AUTOSAR XML (schema 4-2-2)
package /STELLANTIS/EPT/ASWCs
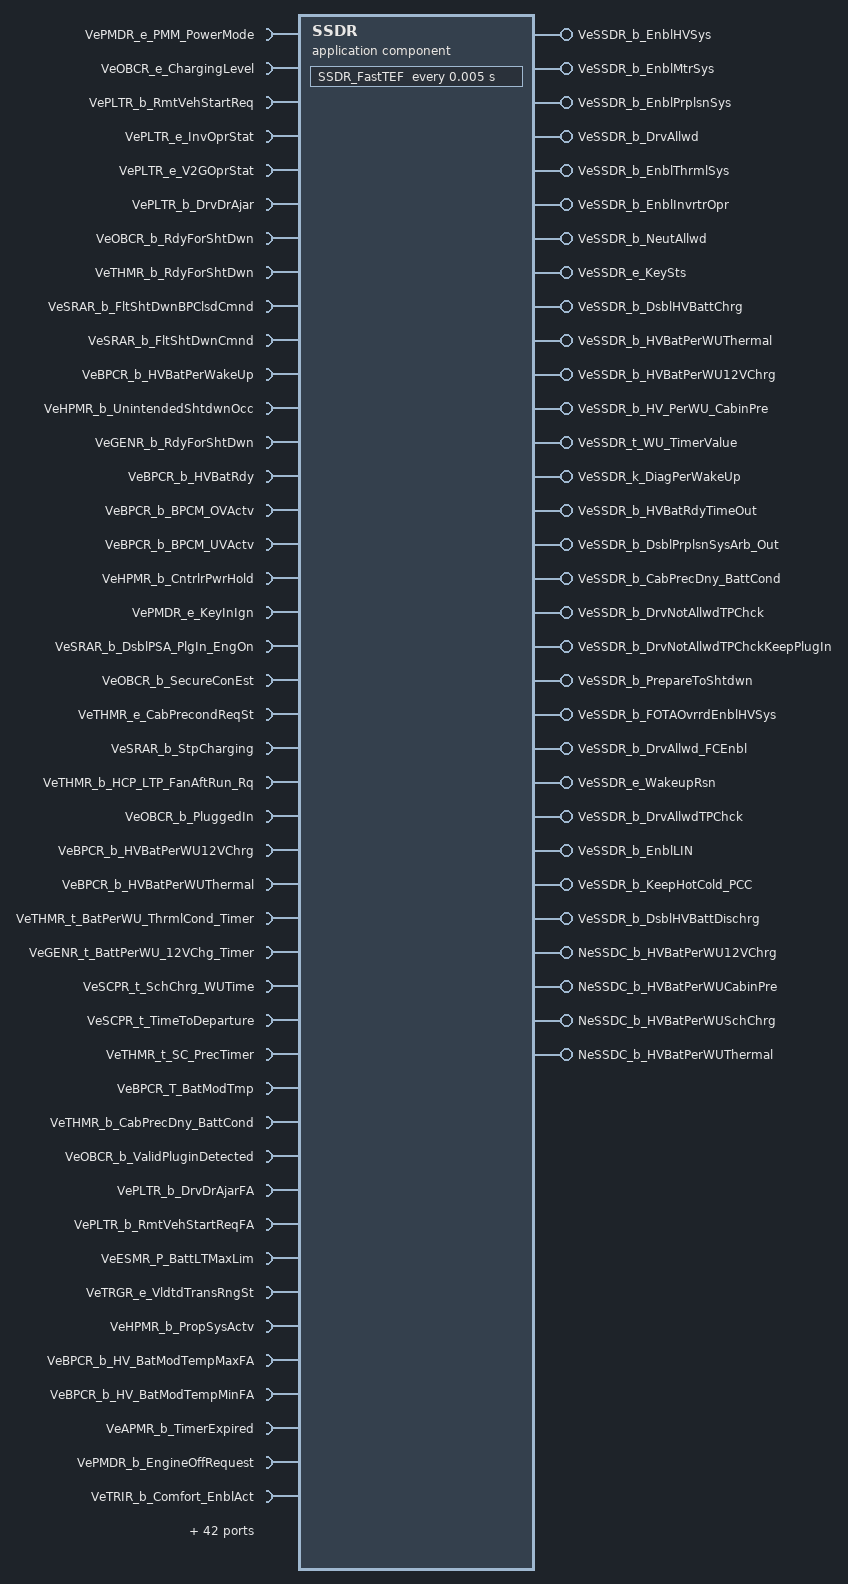
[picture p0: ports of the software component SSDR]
  application sw component type SSDR
    82 x require port:
      VePMDR_e_PMM_PowerMode: nonqueued-receiver-com-spec{data-element=Value, init-value=CePMDR_e_PowerMode_Off}, required-interface=VePMDR_e_PMM_PowerMode
      VeOBCR_e_ChargingLevel: nonqueued-receiver-com-spec{data-element=Value, init-value=CeOBCR_e_ChargingLvlDefault}, required-interface=VeOBCR_e_ChargingLevel
      VePLTR_b_RmtVehStartReq: nonqueued-receiver-com-spec{data-element=Value, init-value=0}, required-interface=VePLTR_b_RmtVehStartReq
      VePLTR_e_InvOprStat: nonqueued-receiver-com-spec{data-element=Value, init-value=CePLTR_e_NoPlgIn_Tools}, required-interface=VePLTR_e_InvOprStat
      VePLTR_e_V2GOprStat: nonqueued-receiver-com-spec{data-element=Value, init-value=CePLTR_e_NoPlgIn}, required-interface=VePLTR_e_V2GOprStat
      VePLTR_b_DrvDrAjar: nonqueued-receiver-com-spec{data-element=Value, init-value=0}, required-interface=VePLTR_b_DrvDrAjar
      VeOBCR_b_RdyForShtDwn: nonqueued-receiver-com-spec{data-element=Value, init-value=0}, required-interface=VeOBCR_b_RdyForShtDwn
      VeTHMR_b_RdyForShtDwn: nonqueued-receiver-com-spec{data-element=Value, init-value=0}, required-interface=VeTHMR_b_RdyForShtDwn
      VeSRAR_b_FltShtDwnBPClsdCmnd: nonqueued-receiver-com-spec{data-element=Value, init-value=0}, required-interface=VeSRAR_b_FltShtDwnBPClsdCmnd
      VeSRAR_b_FltShtDwnCmnd: nonqueued-receiver-com-spec{data-element=Value, init-value=0}, required-interface=VeSRAR_b_FltShtDwnCmnd
      VeBPCR_b_HVBatPerWakeUp: nonqueued-receiver-com-spec{data-element=Value, init-value=0}, required-interface=VeBPCR_b_HVBatPerWakeUp
      VeHPMR_b_UnintendedShtdwnOcc: nonqueued-receiver-com-spec{data-element=Value, init-value=0}, required-interface=VeHPMR_b_UnintendedShtdwnOcc
      VeGENR_b_RdyForShtDwn: nonqueued-receiver-com-spec{data-element=Value, init-value=0}, required-interface=VeGENR_b_RdyForShtDwn
      VeBPCR_b_HVBatRdy: nonqueued-receiver-com-spec{data-element=Value, init-value=0}, required-interface=VeBPCR_b_HVBatRdy
      VeBPCR_b_BPCM_OVActv: nonqueued-receiver-com-spec{data-element=Value, init-value=0}, required-interface=VeBPCR_b_BPCM_OVActv
      VeBPCR_b_BPCM_UVActv: nonqueued-receiver-com-spec{data-element=Value, init-value=0}, required-interface=VeBPCR_b_BPCM_UVActv
      VeHPMR_b_CntrlrPwrHold: nonqueued-receiver-com-spec{data-element=Value, init-value=0}, required-interface=VeHPMR_b_CntrlrPwrHold
      VePMDR_e_KeyInIgn: nonqueued-receiver-com-spec{data-element=Value, init-value=CePMDR_e_KeyInIgn_DEFAULT}, required-interface=VePMDR_e_KeyInIgn
      VeSRAR_b_DsblPSA_PlgIn_EngOn: nonqueued-receiver-com-spec{data-element=Value, init-value=0}, required-interface=VeSRAR_b_DsblPSA_PlgIn_EngOn
      VeOBCR_b_SecureConEst: nonqueued-receiver-com-spec{data-element=Value, init-value=0}, required-interface=VeOBCR_b_SecureConEst
      VeTHMR_e_CabPrecondReqSt: nonqueued-receiver-com-spec{data-element=Value, init-value=CeTPCR_e_CabinPrec_Dflt}, required-interface=VeTHMR_e_CabPrecondReqSt
      VeSRAR_b_StpCharging: nonqueued-receiver-com-spec{data-element=Value, init-value=0}, required-interface=VeSRAR_b_StpCharging
      VeTHMR_b_HCP_LTP_FanAftRun_Rq: nonqueued-receiver-com-spec{data-element=Value, init-value=0}, required-interface=VeTHMR_b_HCP_LTP_FanAftRun_Rq
      VeOBCR_b_PluggedIn: nonqueued-receiver-com-spec{data-element=Value, init-value=0}, required-interface=VeOBCR_b_PluggedIn
      VeBPCR_b_HVBatPerWU12VChrg: nonqueued-receiver-com-spec{data-element=Value, init-value=0}, required-interface=VeBPCR_b_HVBatPerWU12VChrg
      VeBPCR_b_HVBatPerWUThermal: nonqueued-receiver-com-spec{data-element=Value, init-value=0}, required-interface=VeBPCR_b_HVBatPerWUThermal
      VeTHMR_t_BatPerWU_ThrmlCond_Timer: nonqueued-receiver-com-spec{data-element=Value, init-value=0}, required-interface=VeTHMR_t_BatPerWU_ThrmlCond_Timer
      VeGENR_t_BattPerWU_12VChg_Timer: nonqueued-receiver-com-spec{data-element=Value, init-value=0}, required-interface=VeGENR_t_BattPerWU_12VChg_Timer
      VeSCPR_t_SchChrg_WUTime: nonqueued-receiver-com-spec{data-element=Value, init-value=0}, required-interface=VeSCPR_t_SchChrg_WUTime
      VeSCPR_t_TimeToDeparture: nonqueued-receiver-com-spec{data-element=Value, init-value=0}, required-interface=VeSCPR_t_TimeToDeparture
      VeTHMR_t_SC_PrecTimer: nonqueued-receiver-com-spec{data-element=Value, init-value=0}, required-interface=VeTHMR_t_SC_PrecTimer
      VeBPCR_T_BatModTmp: nonqueued-receiver-com-spec{data-element=Value, init-value=0}, required-interface=VeBPCR_T_BatModTmp
      VeTHMR_b_CabPrecDny_BattCond: nonqueued-receiver-com-spec{data-element=Value, init-value=0}, required-interface=VeTHMR_b_CabPrecDny_BattCond
      VeOBCR_b_ValidPluginDetected: nonqueued-receiver-com-spec{data-element=Value, init-value=0}, required-interface=VeOBCR_b_ValidPluginDetected
      VePLTR_b_DrvDrAjarFA: nonqueued-receiver-com-spec{data-element=Value, init-value=0}, required-interface=VePLTR_b_DrvDrAjarFA
      VePLTR_b_RmtVehStartReqFA: nonqueued-receiver-com-spec{data-element=Value, init-value=0}, required-interface=VePLTR_b_RmtVehStartReqFA
      VeESMR_P_BattLTMaxLim: nonqueued-receiver-com-spec{data-element=Value, init-value=0}, required-interface=VeESMR_P_BattLTMaxLim
      VeTRGR_e_VldtdTransRngSt: nonqueued-receiver-com-spec{data-element=Value, init-value=CeTRGR_e_NoSelectionAvailable}, required-interface=VeTRGR_e_VldtdTransRngSt
      VeHPMR_b_PropSysActv: nonqueued-receiver-com-spec{data-element=Value, init-value=0}, required-interface=VeHPMR_b_PropSysActv
      VeBPCR_b_HV_BatModTempMaxFA: nonqueued-receiver-com-spec{data-element=Value, init-value=0}, required-interface=VeBPCR_b_HV_BatModTempMaxFA
      VeBPCR_b_HV_BatModTempMinFA: nonqueued-receiver-com-spec{data-element=Value, init-value=0}, required-interface=VeBPCR_b_HV_BatModTempMinFA
      VeAPMR_b_TimerExpired: nonqueued-receiver-com-spec{data-element=Value, init-value=0}, required-interface=VeAPMR_b_TimerExpired
      VePMDR_b_EngineOffRequest: nonqueued-receiver-com-spec{data-element=Value, init-value=0}, required-interface=VePMDR_b_EngineOffRequest
      VeTRIR_b_Comfort_EnblAct: nonqueued-receiver-com-spec{data-element=Value, init-value=0}, required-interface=VeTRIR_b_Comfort_EnblAct
      VeTPCR_e_KeepHotColdSts: nonqueued-receiver-com-spec{data-element=Value, init-value=CeTPCR_e_NotActive}, required-interface=VeTPCR_e_KeepHotColdSts
      VeBRKR_e_BrkPedalDscrtInpt: nonqueued-receiver-com-spec{data-element=Value, init-value=CeBRKR_e_BrkNotApplied}, required-interface=VeBRKR_e_BrkPedalDscrtInpt
      VeTRGR_e_ESMTransRngSt: nonqueued-receiver-com-spec{data-element=Value, init-value=CeTRGR_e_NoSelectionAvailable}, required-interface=VeTRGR_e_ESMTransRngSt
      VePLTR_e_LSMDExtReleaseLockReq: nonqueued-receiver-com-spec{data-element=Value, init-value=CePLTR_e_NotActive}, required-interface=VePLTR_e_LSMDExtReleaseLockReq
      VePLTR_b_HotEnablerReq: nonqueued-receiver-com-spec{data-element=Value, init-value=0}, required-interface=VePLTR_b_HotEnablerReq
      VeSCPR_e_InitStatus: nonqueued-receiver-com-spec{data-element=Value, init-value=CeSCPR_e_InitDefault}, required-interface=VeSCPR_e_InitStatus
      VePMTR_b_ThrmlShtdwnReqHonrd: nonqueued-receiver-com-spec{data-element=Value, init-value=0}, required-interface=VePMTR_b_ThrmlShtdwnReqHonrd
      VeHPMR_b_PrepareToShtdwn: nonqueued-receiver-com-spec{data-element=Value, init-value=0}, required-interface=VeHPMR_b_PrepareToShtdwn
      VeCITR_e_FOTA_Install_Type: nonqueued-receiver-com-spec{data-element=Value, init-value=CeCITR_e_NoFOTA}, required-interface=VeCITR_e_FOTA_Install_Type
      VeSCPR_b_FOTASchCnflct: nonqueued-receiver-com-spec{data-element=Value, init-value=0}, required-interface=VeSCPR_b_FOTASchCnflct
      VeFCPR_e_FCPS_HTCoolReq: nonqueued-receiver-com-spec{data-element=Value, init-value=CeFCPR_e_No_Request}, required-interface=VeFCPR_e_FCPS_HTCoolReq
      VeFCPR_e_ActualMode: nonqueued-receiver-com-spec{data-element=Value, init-value=CeFCPR_e_ActualMode_NotAvailable}, required-interface=VeFCPR_e_ActualMode
      VeBPCR_e_HV_BatCntctrStat: nonqueued-receiver-com-spec{data-element=Value, init-value=CeHVTR_e_Open}, required-interface=VeBPCR_e_HV_BatCntctrStat
      VeCITR_b_ChargeNow: nonqueued-receiver-com-spec{data-element=Value, init-value=0}, required-interface=VeCITR_b_ChargeNow
      VeCITR_b_TBM_ChargeNow: nonqueued-receiver-com-spec{data-element=Value, init-value=0}, required-interface=VeCITR_b_TBM_ChargeNow
      VeCITR_b_TBM_Sch1_Submit: nonqueued-receiver-com-spec{data-element=Value, init-value=0}, required-interface=VeCITR_b_TBM_Sch1_Submit
      VeCITR_b_HU_Sch1_Submit: nonqueued-receiver-com-spec{data-element=Value, init-value=0}, required-interface=VeCITR_b_HU_Sch1_Submit
      VeCITR_b_TBM_Sch2_Submit: nonqueued-receiver-com-spec{data-element=Value, init-value=0}, required-interface=VeCITR_b_TBM_Sch2_Submit
      VeCITR_b_HU_Sch2_Submit: nonqueued-receiver-com-spec{data-element=Value, init-value=0}, required-interface=VeCITR_b_HU_Sch2_Submit
      VeCITR_b_HU_Sch3_Submit: nonqueued-receiver-com-spec{data-element=Value, init-value=0}, required-interface=VeCITR_b_HU_Sch3_Submit
      VeCITR_b_TBM_Sch3_Submit: nonqueued-receiver-com-spec{data-element=Value, init-value=0}, required-interface=VeCITR_b_TBM_Sch3_Submit
      VeCITR_b_HU_Sch4_Submit: nonqueued-receiver-com-spec{data-element=Value, init-value=0}, required-interface=VeCITR_b_HU_Sch4_Submit
      VeCITR_b_TBM_Sch4_Submit: nonqueued-receiver-com-spec{data-element=Value, init-value=0}, required-interface=VeCITR_b_TBM_Sch4_Submit
      VeTRGR_b_Secured_To_Shtdwn: nonqueued-receiver-com-spec{data-element=Value, init-value=0}, required-interface=VeTRGR_b_Secured_To_Shtdwn
      VeVTLR_b_Rdy4ShtDwn: nonqueued-receiver-com-spec{data-element=Value, init-value=0}, required-interface=VeVTLR_b_Rdy4ShtDwn
      VeOBCR_b_SecureConnV2L: nonqueued-receiver-com-spec{data-element=Value, init-value=0}, required-interface=VeOBCR_b_SecureConnV2L
      VeESSR_e_EngStartStopSt: nonqueued-receiver-com-spec{data-element=Value, init-value=CeESSR_e_EngOff}, required-interface=VeESSR_e_EngStartStopSt
      VeBPCR_Pct_HV_BatPackSOC_Arb: nonqueued-receiver-com-spec{data-element=Value, init-value=0}, required-interface=VeBPCR_Pct_HV_BatPackSOC_Arb
      VeVTLR_b_OnboardPP1_Dtctd: nonqueued-receiver-com-spec{data-element=Value, init-value=0}, required-interface=VeVTLR_b_OnboardPP1_Dtctd
      VeVTLR_b_OnboardPP2_Dtctd: nonqueued-receiver-com-spec{data-element=Value, init-value=0}, required-interface=VeVTLR_b_OnboardPP2_Dtctd
      VeVTLR_b_Rdy4ShtDwn_OnboardPP1: nonqueued-receiver-com-spec{data-element=Value, init-value=0}, required-interface=VeVTLR_b_Rdy4ShtDwn_OnboardPP1
      VeVTLR_b_Rdy4ShtDwn_OnboardPP2: nonqueued-receiver-com-spec{data-element=Value, init-value=0}, required-interface=VeVTLR_b_Rdy4ShtDwn_OnboardPP2
      VeHPMR_b_HVFltStpChrg: nonqueued-receiver-com-spec{data-element=Value, init-value=0}, required-interface=VeHPMR_b_HVFltStpChrg
      VePLTR_b_InFieldMode: nonqueued-receiver-com-spec{data-element=Value, init-value=0}, required-interface=VePLTR_b_InFieldMode
      VeTRIR_b_Comfort_EnblAct_FA: nonqueued-receiver-com-spec{data-element=Value, init-value=0}, required-interface=VeTRIR_b_Comfort_EnblAct_FA
      VeVDVR_b_Rdy4ShtDwn: nonqueued-receiver-com-spec{data-element=Value, init-value=0}, required-interface=VeVDVR_b_Rdy4ShtDwn
      VeBPCR_b_HV_AuxLoadOffReq: nonqueued-receiver-com-spec{data-element=Value, init-value=0}, required-interface=VeBPCR_b_HV_AuxLoadOffReq
      VeHPMR_e_HybSysSt: nonqueued-receiver-com-spec{data-element=Value, init-value=CeHPMR_e_POWERUP}, required-interface=VeHPMR_e_HybSysSt
    27 x provide port:
      VeSSDR_b_EnblHVSys: nonqueued-sender-com-spec{data-element=Value, init-value=0}, provided-interface=VeSSDR_b_EnblHVSys
      VeSSDR_b_EnblMtrSys: nonqueued-sender-com-spec{data-element=Value, init-value=0}, provided-interface=VeSSDR_b_EnblMtrSys
      VeSSDR_b_EnblPrplsnSys: nonqueued-sender-com-spec{data-element=Value, init-value=0}, provided-interface=VeSSDR_b_EnblPrplsnSys
      VeSSDR_b_DrvAllwd: nonqueued-sender-com-spec{data-element=Value, init-value=0}, provided-interface=VeSSDR_b_DrvAllwd
      VeSSDR_b_EnblThrmlSys: nonqueued-sender-com-spec{data-element=Value, init-value=0}, provided-interface=VeSSDR_b_EnblThrmlSys
      VeSSDR_b_EnblInvrtrOpr: nonqueued-sender-com-spec{data-element=Value, init-value=0}, provided-interface=VeSSDR_b_EnblInvrtrOpr
      VeSSDR_b_NeutAllwd: nonqueued-sender-com-spec{data-element=Value, init-value=0}, provided-interface=VeSSDR_b_NeutAllwd
      VeSSDR_e_KeySts: nonqueued-sender-com-spec{data-element=Value, init-value=CeSSDR_e_KeyOff}, provided-interface=VeSSDR_e_KeySts
      VeSSDR_b_DsblHVBattChrg: nonqueued-sender-com-spec{data-element=Value, init-value=0}, provided-interface=VeSSDR_b_DsblHVBattChrg
      VeSSDR_b_HVBatPerWUThermal: nonqueued-sender-com-spec{data-element=Value, init-value=0}, provided-interface=VeSSDR_b_HVBatPerWUThermal
      VeSSDR_b_HVBatPerWU12VChrg: nonqueued-sender-com-spec{data-element=Value, init-value=0}, provided-interface=VeSSDR_b_HVBatPerWU12VChrg
      VeSSDR_b_HV_PerWU_CabinPre: nonqueued-sender-com-spec{data-element=Value, init-value=0}, provided-interface=VeSSDR_b_HV_PerWU_CabinPre
      VeSSDR_t_WU_TimerValue: nonqueued-sender-com-spec{data-element=Value, init-value=0}, provided-interface=VeSSDR_t_WU_TimerValue
      VeSSDR_k_DiagPerWakeUp: nonqueued-sender-com-spec{data-element=Value, init-value=0}, provided-interface=VeSSDR_k_DiagPerWakeUp
      VeSSDR_b_HVBatRdyTimeOut: nonqueued-sender-com-spec{data-element=Value, init-value=0}, provided-interface=VeSSDR_b_HVBatRdyTimeOut
      VeSSDR_b_DsblPrplsnSysArb_Out: nonqueued-sender-com-spec{data-element=Value, init-value=0}, provided-interface=VeSSDR_b_DsblPrplsnSysArb_Out
      VeSSDR_b_CabPrecDny_BattCond: nonqueued-sender-com-spec{data-element=Value, init-value=0}, provided-interface=VeSSDR_b_CabPrecDny_BattCond
      VeSSDR_b_DrvNotAllwdTPChck: nonqueued-sender-com-spec{data-element=Value, init-value=0}, provided-interface=VeSSDR_b_DrvNotAllwdTPChck
      VeSSDR_b_DrvNotAllwdTPChckKeepPlugIn: nonqueued-sender-com-spec{data-element=Value, init-value=0}, provided-interface=VeSSDR_b_DrvNotAllwdTPChckKeepPlugIn
      VeSSDR_b_PrepareToShtdwn: nonqueued-sender-com-spec{data-element=Value, init-value=0}, provided-interface=VeSSDR_b_PrepareToShtdwn
      VeSSDR_b_FOTAOvrrdEnblHVSys: nonqueued-sender-com-spec{data-element=Value, init-value=0}, provided-interface=VeSSDR_b_FOTAOvrrdEnblHVSys
      VeSSDR_b_DrvAllwd_FCEnbl: nonqueued-sender-com-spec{data-element=Value, init-value=0}, provided-interface=VeSSDR_b_DrvAllwd_FCEnbl
      VeSSDR_e_WakeupRsn: nonqueued-sender-com-spec{data-element=Value, init-value=0}, provided-interface=VeSSDR_e_WakeupRsn
      VeSSDR_b_DrvAllwdTPChck: nonqueued-sender-com-spec{data-element=Value, init-value=0}, provided-interface=VeSSDR_b_DrvAllwdTPChck
      VeSSDR_b_EnblLIN: nonqueued-sender-com-spec{data-element=Value, init-value=0}, provided-interface=VeSSDR_b_EnblLIN
      VeSSDR_b_KeepHotCold_PCC: nonqueued-sender-com-spec{data-element=Value, init-value=0}, provided-interface=VeSSDR_b_KeepHotCold_PCC
      VeSSDR_b_DsblHVBattDischrg: nonqueued-sender-com-spec{data-element=Value, init-value=0}, provided-interface=VeSSDR_b_DsblHVBattDischrg
    4 x require port:
      NeSSDC_b_HVBatPerWU12VChrg_Rx: nv-require-com-spec{init-value=0, variable=NeSSDC_b_HVBatPerWU12VChrg}, required-interface=NeSSDC_b_HVBatPerWU12VChrg
      NeSSDC_b_HVBatPerWUCabinPre_Rx: nv-require-com-spec{init-value=0, variable=NeSSDC_b_HVBatPerWUCabinPre}, required-interface=NeSSDC_b_HVBatPerWUCabinPre
      NeSSDC_b_HVBatPerWUSchChrg_Rx: nv-require-com-spec{init-value=0, variable=NeSSDC_b_HVBatPerWUSchChrg}, required-interface=NeSSDC_b_HVBatPerWUSchChrg
      NeSSDC_b_HVBatPerWUThermal_Rx: nv-require-com-spec{init-value=0, variable=NeSSDC_b_HVBatPerWUThermal}, required-interface=NeSSDC_b_HVBatPerWUThermal
    4 x provide port:
      NeSSDC_b_HVBatPerWU12VChrg: nv-provide-com-spec{ram-block-init-value=0, variable=NeSSDC_b_HVBatPerWU12VChrg}, provided-interface=NeSSDC_b_HVBatPerWU12VChrg
      NeSSDC_b_HVBatPerWUCabinPre: nv-provide-com-spec{ram-block-init-value=0, variable=NeSSDC_b_HVBatPerWUCabinPre}, provided-interface=NeSSDC_b_HVBatPerWUCabinPre
      NeSSDC_b_HVBatPerWUSchChrg: nv-provide-com-spec{ram-block-init-value=0, variable=NeSSDC_b_HVBatPerWUSchChrg}, provided-interface=NeSSDC_b_HVBatPerWUSchChrg
      NeSSDC_b_HVBatPerWUThermal: nv-provide-com-spec{ram-block-init-value=0, variable=NeSSDC_b_HVBatPerWUThermal}, provided-interface=NeSSDC_b_HVBatPerWUThermal
    behavior IB_SSDR: data-type-mapping=msADTtoIDTMapping, handle-termination-and-restart=NO-SUPPORT, included-data-type-set=data-type=[TeSSDR_e_HVBattChrgStat, TeSSDR_e_InvOprStat, TeSSDR_e_V2GOprStat]
      timing event Event_FastTEF: start-on-event=SSDR_FastTEF, period=0.005
      init event Event_SSDR_ac_Init: start-on-event=SSDR_ac_Init
      init event Event_PwrOn: start-on-event=SSDR_PwrOn
      init event Event_PwrOff: start-on-event=SSDR_PwrOff
      4 x runnable:
        SSDR_ac_Init
          data-send-points:
            access OUT_VeSSDR_e_KeySts_Value: accessed-variable=VeSSDR_e_KeySts.Value
        SSDR_PwrOn
          data-receive-point-by-arguments:
            4 x access:
              IN_NeSSDC_b_HVBatPerWU12VChrg_Rx_NeSSDC_b_HVBatPerWU12VChrg: accessed-variable=NeSSDC_b_HVBatPerWU12VChrg_Rx.NeSSDC_b_HVBatPerWU12VChrg
              IN_NeSSDC_b_HVBatPerWUCabinPre_Rx_NeSSDC_b_HVBatPerWUCabinPre: accessed-variable=NeSSDC_b_HVBatPerWUCabinPre_Rx.NeSSDC_b_HVBatPerWUCabinPre
              IN_NeSSDC_b_HVBatPerWUSchChrg_Rx_NeSSDC_b_HVBatPerWUSchChrg: accessed-variable=NeSSDC_b_HVBatPerWUSchChrg_Rx.NeSSDC_b_HVBatPerWUSchChrg
              IN_NeSSDC_b_HVBatPerWUThermal_Rx_NeSSDC_b_HVBatPerWUThermal: accessed-variable=NeSSDC_b_HVBatPerWUThermal_Rx.NeSSDC_b_HVBatPerWUThermal
          data-send-points:
            27 x access:
              OUT_VeSSDR_b_EnblHVSys_Value: accessed-variable=VeSSDR_b_EnblHVSys.Value
              OUT_VeSSDR_b_EnblMtrSys_Value: accessed-variable=VeSSDR_b_EnblMtrSys.Value
              OUT_VeSSDR_b_NeutAllwd_Value: accessed-variable=VeSSDR_b_NeutAllwd.Value
              OUT_VeSSDR_e_KeySts_Value: accessed-variable=VeSSDR_e_KeySts.Value
              OUT_VeSSDR_e_WakeupRsn_Value: accessed-variable=VeSSDR_e_WakeupRsn.Value
              OUT_VeSSDR_b_DsblHVBattChrg_Value: accessed-variable=VeSSDR_b_DsblHVBattChrg.Value
              OUT_VeSSDR_b_HVBatPerWUThermal_Value: accessed-variable=VeSSDR_b_HVBatPerWUThermal.Value
              OUT_VeSSDR_b_HVBatPerWU12VChrg_Value: accessed-variable=VeSSDR_b_HVBatPerWU12VChrg.Value
              OUT_VeSSDR_b_DrvAllwdTPChck_Value: accessed-variable=VeSSDR_b_DrvAllwdTPChck.Value
              OUT_VeSSDR_b_HV_PerWU_CabinPre_Value: accessed-variable=VeSSDR_b_HV_PerWU_CabinPre.Value
              OUT_VeSSDR_t_WU_TimerValue_Value: accessed-variable=VeSSDR_t_WU_TimerValue.Value
              OUT_VeSSDR_b_HVBatRdyTimeOut_Value: accessed-variable=VeSSDR_b_HVBatRdyTimeOut.Value
              OUT_VeSSDR_b_EnblPrplsnSys_Value: accessed-variable=VeSSDR_b_EnblPrplsnSys.Value
              OUT_VeSSDR_b_DsblPrplsnSysArb_Out_Value: accessed-variable=VeSSDR_b_DsblPrplsnSysArb_Out.Value
              OUT_VeSSDR_b_CabPrecDny_BattCond_Value: accessed-variable=VeSSDR_b_CabPrecDny_BattCond.Value
              OUT_VeSSDR_k_DiagPerWakeUp_Value: accessed-variable=VeSSDR_k_DiagPerWakeUp.Value
              OUT_VeSSDR_b_DrvNotAllwdTPChck_Value: accessed-variable=VeSSDR_b_DrvNotAllwdTPChck.Value
              OUT_VeSSDR_b_EnblLIN_Value: accessed-variable=VeSSDR_b_EnblLIN.Value
              OUT_VeSSDR_b_KeepHotCold_PCC_Value: accessed-variable=VeSSDR_b_KeepHotCold_PCC.Value
              OUT_VeSSDR_b_DrvAllwd_Value: accessed-variable=VeSSDR_b_DrvAllwd.Value
              OUT_VeSSDR_b_DrvNotAllwdTPChckKeepPlugIn_Value: accessed-variable=VeSSDR_b_DrvNotAllwdTPChckKeepPlugIn.Value
              OUT_VeSSDR_b_EnblThrmlSys_Value: accessed-variable=VeSSDR_b_EnblThrmlSys.Value
              OUT_VeSSDR_b_EnblInvrtrOpr_Value: accessed-variable=VeSSDR_b_EnblInvrtrOpr.Value
              OUT_VeSSDR_b_PrepareToShtdwn_Value: accessed-variable=VeSSDR_b_PrepareToShtdwn.Value
              OUT_VeSSDR_b_FOTAOvrrdEnblHVSys_Value: accessed-variable=VeSSDR_b_FOTAOvrrdEnblHVSys.Value
              OUT_VeSSDR_b_DrvAllwd_FCEnbl_Value: accessed-variable=VeSSDR_b_DrvAllwd_FCEnbl.Value
              OUT_VeSSDR_b_DsblHVBattDischrg_Value: accessed-variable=VeSSDR_b_DsblHVBattDischrg.Value
        SSDR_FastTEF
          data-receive-point-by-arguments:
            82 x access:
              IN_VeAPMR_b_TimerExpired_Value: accessed-variable=VeAPMR_b_TimerExpired.Value
              IN_VeBPCR_Pct_HV_BatPackSOC_Arb_Value: accessed-variable=VeBPCR_Pct_HV_BatPackSOC_Arb.Value
              IN_VeBPCR_T_BatModTmp_Value: accessed-variable=VeBPCR_T_BatModTmp.Value
              IN_VeBPCR_b_BPCM_OVActv_Value: accessed-variable=VeBPCR_b_BPCM_OVActv.Value
              IN_VeBPCR_b_BPCM_UVActv_Value: accessed-variable=VeBPCR_b_BPCM_UVActv.Value
              IN_VeBPCR_b_HVBatPerWU12VChrg_Value: accessed-variable=VeBPCR_b_HVBatPerWU12VChrg.Value
              IN_VeBPCR_b_HVBatPerWUThermal_Value: accessed-variable=VeBPCR_b_HVBatPerWUThermal.Value
              IN_VeBPCR_b_HVBatPerWakeUp_Value: accessed-variable=VeBPCR_b_HVBatPerWakeUp.Value
              IN_VeBPCR_b_HVBatRdy_Value: accessed-variable=VeBPCR_b_HVBatRdy.Value
              IN_VeBPCR_b_HV_AuxLoadOffReq_Value: accessed-variable=VeBPCR_b_HV_AuxLoadOffReq.Value
              IN_VeBPCR_b_HV_BatModTempMaxFA_Value: accessed-variable=VeBPCR_b_HV_BatModTempMaxFA.Value
              IN_VeBPCR_b_HV_BatModTempMinFA_Value: accessed-variable=VeBPCR_b_HV_BatModTempMinFA.Value
              IN_VeBPCR_e_HV_BatCntctrStat_Value: accessed-variable=VeBPCR_e_HV_BatCntctrStat.Value
              IN_VeBRKR_e_BrkPedalDscrtInpt_Value: accessed-variable=VeBRKR_e_BrkPedalDscrtInpt.Value
              IN_VeCITR_b_ChargeNow_Value: accessed-variable=VeCITR_b_ChargeNow.Value
              IN_VeCITR_b_HU_Sch{1..4}_Submit_Value: accessed-variable=VeCITR_b_HU_Sch{1..4}_Submit.Value
              IN_VeCITR_b_TBM_ChargeNow_Value: accessed-variable=VeCITR_b_TBM_ChargeNow.Value
              IN_VeCITR_b_TBM_Sch{1..4}_Submit_Value: accessed-variable=VeCITR_b_TBM_Sch{1..4}_Submit.Value
              IN_VeCITR_e_FOTA_Install_Type_Value: accessed-variable=VeCITR_e_FOTA_Install_Type.Value
              IN_VeESMR_P_BattLTMaxLim_Value: accessed-variable=VeESMR_P_BattLTMaxLim.Value
              IN_VeESSR_e_EngStartStopSt_Value: accessed-variable=VeESSR_e_EngStartStopSt.Value
              IN_VeFCPR_e_ActualMode_Value: accessed-variable=VeFCPR_e_ActualMode.Value
              IN_VeFCPR_e_FCPS_HTCoolReq_Value: accessed-variable=VeFCPR_e_FCPS_HTCoolReq.Value
              IN_VeGENR_b_RdyForShtDwn_Value: accessed-variable=VeGENR_b_RdyForShtDwn.Value
              IN_VeGENR_t_BattPerWU_12VChg_Timer_Value: accessed-variable=VeGENR_t_BattPerWU_12VChg_Timer.Value
              IN_VeHPMR_b_CntrlrPwrHold_Value: accessed-variable=VeHPMR_b_CntrlrPwrHold.Value
              IN_VeHPMR_b_HVFltStpChrg_Value: accessed-variable=VeHPMR_b_HVFltStpChrg.Value
              IN_VeHPMR_b_PrepareToShtdwn_Value: accessed-variable=VeHPMR_b_PrepareToShtdwn.Value
              IN_VeHPMR_b_PropSysActv_Value: accessed-variable=VeHPMR_b_PropSysActv.Value
              IN_VeHPMR_b_UnintendedShtdwnOcc_Value: accessed-variable=VeHPMR_b_UnintendedShtdwnOcc.Value
              IN_VeHPMR_e_HybSysSt_Value: accessed-variable=VeHPMR_e_HybSysSt.Value
              IN_VeOBCR_b_PluggedIn_Value: accessed-variable=VeOBCR_b_PluggedIn.Value
              IN_VeOBCR_b_RdyForShtDwn_Value: accessed-variable=VeOBCR_b_RdyForShtDwn.Value
              IN_VeOBCR_b_SecureConEst_Value: accessed-variable=VeOBCR_b_SecureConEst.Value
              IN_VeOBCR_b_SecureConnV2L_Value: accessed-variable=VeOBCR_b_SecureConnV2L.Value
              IN_VeOBCR_b_ValidPluginDetected_Value: accessed-variable=VeOBCR_b_ValidPluginDetected.Value
              IN_VeOBCR_e_ChargingLevel_Value: accessed-variable=VeOBCR_e_ChargingLevel.Value
              IN_VePLTR_b_DrvDrAjar_Value: accessed-variable=VePLTR_b_DrvDrAjar.Value
              IN_VePLTR_b_DrvDrAjarFA_Value: accessed-variable=VePLTR_b_DrvDrAjarFA.Value
              IN_VePLTR_b_HotEnablerReq_Value: accessed-variable=VePLTR_b_HotEnablerReq.Value
              IN_VePLTR_b_InFieldMode_Value: accessed-variable=VePLTR_b_InFieldMode.Value
              IN_VePLTR_b_RmtVehStartReq_Value: accessed-variable=VePLTR_b_RmtVehStartReq.Value
              IN_VePLTR_b_RmtVehStartReqFA_Value: accessed-variable=VePLTR_b_RmtVehStartReqFA.Value
              IN_VePLTR_e_InvOprStat_Value: accessed-variable=VePLTR_e_InvOprStat.Value
              IN_VePLTR_e_LSMDExtReleaseLockReq_Value: accessed-variable=VePLTR_e_LSMDExtReleaseLockReq.Value
              IN_VePLTR_e_V2GOprStat_Value: accessed-variable=VePLTR_e_V2GOprStat.Value
              IN_VePMDR_b_EngineOffRequest_Value: accessed-variable=VePMDR_b_EngineOffRequest.Value
              IN_VePMDR_e_KeyInIgn_Value: accessed-variable=VePMDR_e_KeyInIgn.Value
              IN_VePMDR_e_PMM_PowerMode_Value: accessed-variable=VePMDR_e_PMM_PowerMode.Value
              IN_VePMTR_b_ThrmlShtdwnReqHonrd_Value: accessed-variable=VePMTR_b_ThrmlShtdwnReqHonrd.Value
              IN_VeSCPR_b_FOTASchCnflct_Value: accessed-variable=VeSCPR_b_FOTASchCnflct.Value
              IN_VeSCPR_e_InitStatus_Value: accessed-variable=VeSCPR_e_InitStatus.Value
              IN_VeSCPR_t_SchChrg_WUTime_Value: accessed-variable=VeSCPR_t_SchChrg_WUTime.Value
              IN_VeSCPR_t_TimeToDeparture_Value: accessed-variable=VeSCPR_t_TimeToDeparture.Value
              IN_VeSRAR_b_DsblPSA_PlgIn_EngOn_Value: accessed-variable=VeSRAR_b_DsblPSA_PlgIn_EngOn.Value
              IN_VeSRAR_b_FltShtDwnBPClsdCmnd_Value: accessed-variable=VeSRAR_b_FltShtDwnBPClsdCmnd.Value
              IN_VeSRAR_b_FltShtDwnCmnd_Value: accessed-variable=VeSRAR_b_FltShtDwnCmnd.Value
              IN_VeSRAR_b_StpCharging_Value: accessed-variable=VeSRAR_b_StpCharging.Value
              IN_VeTHMR_b_CabPrecDny_BattCond_Value: accessed-variable=VeTHMR_b_CabPrecDny_BattCond.Value
              IN_VeTHMR_b_HCP_LTP_FanAftRun_Rq_Value: accessed-variable=VeTHMR_b_HCP_LTP_FanAftRun_Rq.Value
              IN_VeTHMR_b_RdyForShtDwn_Value: accessed-variable=VeTHMR_b_RdyForShtDwn.Value
              IN_VeTHMR_e_CabPrecondReqSt_Value: accessed-variable=VeTHMR_e_CabPrecondReqSt.Value
              IN_VeTHMR_t_BatPerWU_ThrmlCond_Timer_Value: accessed-variable=VeTHMR_t_BatPerWU_ThrmlCond_Timer.Value
              IN_VeTHMR_t_SC_PrecTimer_Value: accessed-variable=VeTHMR_t_SC_PrecTimer.Value
              IN_VeTPCR_e_KeepHotColdSts_Value: accessed-variable=VeTPCR_e_KeepHotColdSts.Value
              IN_VeTRGR_b_Secured_To_Shtdwn_Value: accessed-variable=VeTRGR_b_Secured_To_Shtdwn.Value
              IN_VeTRGR_e_ESMTransRngSt_Value: accessed-variable=VeTRGR_e_ESMTransRngSt.Value
              IN_VeTRGR_e_VldtdTransRngSt_Value: accessed-variable=VeTRGR_e_VldtdTransRngSt.Value
              IN_VeTRIR_b_Comfort_EnblAct_Value: accessed-variable=VeTRIR_b_Comfort_EnblAct.Value
              IN_VeTRIR_b_Comfort_EnblAct_FA_Value: accessed-variable=VeTRIR_b_Comfort_EnblAct_FA.Value
              IN_VeVDVR_b_Rdy4ShtDwn_Value: accessed-variable=VeVDVR_b_Rdy4ShtDwn.Value
              IN_VeVTLR_b_OnboardPP1_Dtctd_Value: accessed-variable=VeVTLR_b_OnboardPP1_Dtctd.Value
              IN_VeVTLR_b_OnboardPP2_Dtctd_Value: accessed-variable=VeVTLR_b_OnboardPP2_Dtctd.Value
              IN_VeVTLR_b_Rdy4ShtDwn_Value: accessed-variable=VeVTLR_b_Rdy4ShtDwn.Value
              IN_VeVTLR_b_Rdy4ShtDwn_OnboardPP1_Value: accessed-variable=VeVTLR_b_Rdy4ShtDwn_OnboardPP1.Value
              IN_VeVTLR_b_Rdy4ShtDwn_OnboardPP2_Value: accessed-variable=VeVTLR_b_Rdy4ShtDwn_OnboardPP2.Value
          data-send-points:
            27 x access:
              OUT_VeSSDR_b_EnblHVSys_Value: accessed-variable=VeSSDR_b_EnblHVSys.Value
              OUT_VeSSDR_b_EnblMtrSys_Value: accessed-variable=VeSSDR_b_EnblMtrSys.Value
              OUT_VeSSDR_b_NeutAllwd_Value: accessed-variable=VeSSDR_b_NeutAllwd.Value
              OUT_VeSSDR_e_KeySts_Value: accessed-variable=VeSSDR_e_KeySts.Value
              OUT_VeSSDR_e_WakeupRsn_Value: accessed-variable=VeSSDR_e_WakeupRsn.Value
              OUT_VeSSDR_b_DsblHVBattChrg_Value: accessed-variable=VeSSDR_b_DsblHVBattChrg.Value
              OUT_VeSSDR_b_HVBatPerWUThermal_Value: accessed-variable=VeSSDR_b_HVBatPerWUThermal.Value
              OUT_VeSSDR_b_HVBatPerWU12VChrg_Value: accessed-variable=VeSSDR_b_HVBatPerWU12VChrg.Value
              OUT_VeSSDR_b_DrvAllwdTPChck_Value: accessed-variable=VeSSDR_b_DrvAllwdTPChck.Value
              OUT_VeSSDR_b_HV_PerWU_CabinPre_Value: accessed-variable=VeSSDR_b_HV_PerWU_CabinPre.Value
              OUT_VeSSDR_t_WU_TimerValue_Value: accessed-variable=VeSSDR_t_WU_TimerValue.Value
              OUT_VeSSDR_b_HVBatRdyTimeOut_Value: accessed-variable=VeSSDR_b_HVBatRdyTimeOut.Value
              OUT_VeSSDR_b_EnblPrplsnSys_Value: accessed-variable=VeSSDR_b_EnblPrplsnSys.Value
              OUT_VeSSDR_b_DsblPrplsnSysArb_Out_Value: accessed-variable=VeSSDR_b_DsblPrplsnSysArb_Out.Value
              OUT_VeSSDR_b_CabPrecDny_BattCond_Value: accessed-variable=VeSSDR_b_CabPrecDny_BattCond.Value
              OUT_VeSSDR_k_DiagPerWakeUp_Value: accessed-variable=VeSSDR_k_DiagPerWakeUp.Value
              OUT_VeSSDR_b_DrvNotAllwdTPChck_Value: accessed-variable=VeSSDR_b_DrvNotAllwdTPChck.Value
              OUT_VeSSDR_b_EnblLIN_Value: accessed-variable=VeSSDR_b_EnblLIN.Value
              OUT_VeSSDR_b_KeepHotCold_PCC_Value: accessed-variable=VeSSDR_b_KeepHotCold_PCC.Value
              OUT_VeSSDR_b_DrvAllwd_Value: accessed-variable=VeSSDR_b_DrvAllwd.Value
              OUT_VeSSDR_b_DrvNotAllwdTPChckKeepPlugIn_Value: accessed-variable=VeSSDR_b_DrvNotAllwdTPChckKeepPlugIn.Value
              OUT_VeSSDR_b_EnblThrmlSys_Value: accessed-variable=VeSSDR_b_EnblThrmlSys.Value
              OUT_VeSSDR_b_EnblInvrtrOpr_Value: accessed-variable=VeSSDR_b_EnblInvrtrOpr.Value
              OUT_VeSSDR_b_PrepareToShtdwn_Value: accessed-variable=VeSSDR_b_PrepareToShtdwn.Value
              OUT_VeSSDR_b_FOTAOvrrdEnblHVSys_Value: accessed-variable=VeSSDR_b_FOTAOvrrdEnblHVSys.Value
              OUT_VeSSDR_b_DrvAllwd_FCEnbl_Value: accessed-variable=VeSSDR_b_DrvAllwd_FCEnbl.Value
              OUT_VeSSDR_b_DsblHVBattDischrg_Value: accessed-variable=VeSSDR_b_DsblHVBattDischrg.Value
        SSDR_PwrOff
          data-send-points:
            4 x access:
              OUT_NeSSDC_b_HVBatPerWU12VChrg_NeSSDC_b_HVBatPerWU12VChrg: accessed-variable=NeSSDC_b_HVBatPerWU12VChrg.NeSSDC_b_HVBatPerWU12VChrg
              OUT_NeSSDC_b_HVBatPerWUCabinPre_NeSSDC_b_HVBatPerWUCabinPre: accessed-variable=NeSSDC_b_HVBatPerWUCabinPre.NeSSDC_b_HVBatPerWUCabinPre
              OUT_NeSSDC_b_HVBatPerWUSchChrg_NeSSDC_b_HVBatPerWUSchChrg: accessed-variable=NeSSDC_b_HVBatPerWUSchChrg.NeSSDC_b_HVBatPerWUSchChrg
              OUT_NeSSDC_b_HVBatPerWUThermal_NeSSDC_b_HVBatPerWUThermal: accessed-variable=NeSSDC_b_HVBatPerWUThermal.NeSSDC_b_HVBatPerWUThermal
